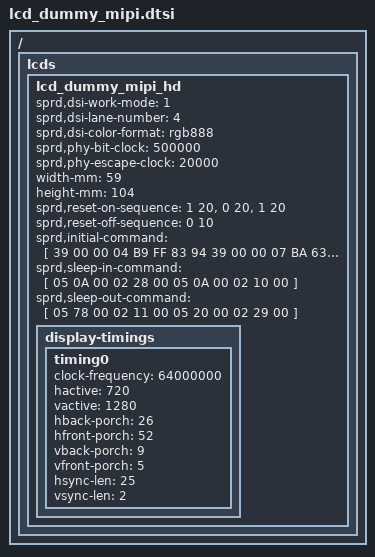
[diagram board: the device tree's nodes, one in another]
/ { lcds {
	lcd_dummy_mipi_hd: lcd_dummy_mipi_hd {

		sprd,dsi-work-mode = <1>; /* video burst mode*/

		sprd,dsi-lane-number = <4>;
		sprd,dsi-color-format = "rgb888";

		sprd,phy-bit-clock = <500000>;
		sprd,phy-escape-clock = <20000>;
	
		width-mm = <59>;
		height-mm = <104>;


		sprd,reset-on-sequence = <1 20>, <0 20>, <1 20>;
		sprd,reset-off-sequence = <0 10>;
	
		sprd,initial-command = [
			39 00 00 04 B9 FF 83 94
			39 00 00 07 BA 63 03 68 6B B2 C0
			39 00 00 0B B1 48 12 72 09 32 44 71 31 4F 35
			39 00 00 06 B2 00 80 64 05 07
			39 00 00 1f B4 26 76 26 76 26 26 05 10 86 35 00 3F 26 76 26 76 26 26 05 10 86 3F 00 FF 81 81 81 81 08 01
			39 00 00 22 D3 00 00 0F 0F 01 01 10 10 32 10 00 00 00 32 15 04 05 04 32 15 14 05 14 37 33 04 04 37 00 00 47 05 40 
			39 00 00 2d D5 18 18 25 24 27 26 11 10 15 14 13 12 17 16 01 00 18 18 18 18 18 18 18 18 18 18 05 04 03 02 07 06 18 18 18 18 21 20 23 22 18 18 18 18
			39 00 00 2d D6 18 18 22 23 20 21 12 13 16 17 10 11 14 15 06 07 18 18 18 18 18 18 18 18 18 18 02 03 04 05 00 01 18 18 18 18 26 27 24 25 18 18 18 18
			39 00 00 3b E0 00 03 0B 0E 10 13 17 15 2D 3D 51 51 5E 75 7C 84 94 9A 98 A6 B2 57 57 5A 60 64 6A 72 7F 00 03 0B 0E 10 13 17 15 2D 3D 51 51 5E 75 7C 84 94 9A 98 A6 B2 57 57 5A 60 64 6A 72 7F
			39 00 00 03 B6 4E 4E 
			39 00 00 02 CC 0B 
			39 00 00 03 C0 1F 31 
			39 00 00 02 D2 88 
			39 00 00 02 D4 02 
			39 00 00 02 BD 01 
			39 00 00 02 B1 60 
			39 00 00 02 BD 00 
			39 00 00 08 BF 40 81 50 00 1A FC 01 
			05 78 00 02 11 00
			05 20 00 02 29 00
			];
		sprd,sleep-in-command = [
			05 0A 00 02 28 00
			05 0A 00 02 10 00
			];
		sprd,sleep-out-command = [
			05 78 00 02 11 00
			05 20 00 02 29 00
			];

		display-timings {
			timing0 {
			clock-frequency = <64000000>;
			hactive = <720>;
			vactive = <1280>;
			hback-porch = <26>;
			hfront-porch = <52>;
			vback-porch = <9>;
			vfront-porch = <5>;
			hsync-len = <25>;
			vsync-len = <2>;

			};
		};
	};
}; };
